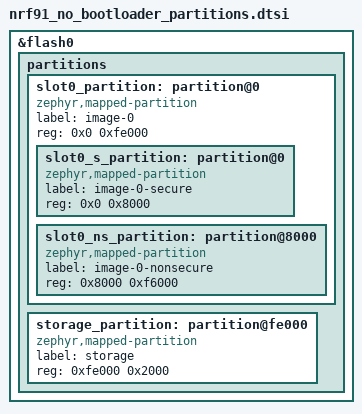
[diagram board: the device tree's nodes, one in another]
/*
 * Copyright (c) 2026 Nordic Semiconductor ASA
 *
 * SPDX-License-Identifier: LicenseRef-Nordic-5-Clause
 */

/delete-node/ &boot_partition;
/delete-node/ &slot0_partition;
/delete-node/ &slot1_partition;
/delete-node/ &tfm_ps_partition;
/delete-node/ &tfm_its_partition;
/delete-node/ &tfm_otp_partition;
/delete-node/ &storage_partition;

&flash0 {
	/*
	 * 0x0000_0000  Primary area			(1016 kB)
	 *   0x0000_0000  Primary secure image		(  32 kB)
	 *   0x0000_8000  Primary non-secure image	( 984 kB)
	 * 0x000f_e000  Settings storage		(   8 kB)
	 */
	partitions {
		ranges;
		#address-cells = <1>;
		#size-cells = <1>;

		slot0_partition: partition@0 {
			compatible = "zephyr,mapped-partition";
			label = "image-0";
			reg = <0x0 0xfe000>;
			ranges = <0x0 0x0 0xfe000>;
			#address-cells = <1>;
			#size-cells = <1>;

			slot0_s_partition: partition@0 {
				compatible = "zephyr,mapped-partition";
				label = "image-0-secure";
				reg = <0x0 0x8000>;
			};

			slot0_ns_partition: partition@8000 {
				compatible = "zephyr,mapped-partition";
				label = "image-0-nonsecure";
				reg = <0x8000 0xf6000>;
			};
		};

		storage_partition: partition@fe000 {
			compatible = "zephyr,mapped-partition";
			label = "storage";
			reg = <0xfe000 0x2000>;
		};
	};
};
